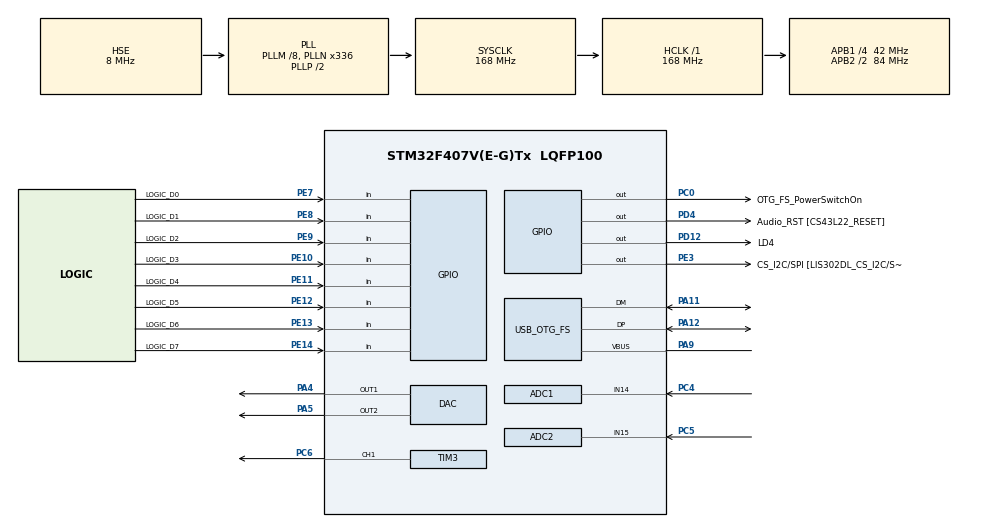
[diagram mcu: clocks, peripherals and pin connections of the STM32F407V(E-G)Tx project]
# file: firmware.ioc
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ADC1.Channel-0\#ChannelRegularConversion=ADC_CHANNEL_14
ADC1.ClockPrescaler=ADC_CLOCK_SYNC_PCLK_DIV4
ADC1.DMAAccessMode=ADC_DMAACCESSMODE_2
ADC1.DMAContinuousRequests=ENABLE
ADC1.ExternalTrigConv=ADC_EXTERNALTRIGCONV_T2_TRGO
ADC1.Mode=ADC_DUALMODE_REGSIMULT
ADC1.NbrOfConversionFlag=1
ADC1.Rank-0\#ChannelRegularConversion=1
ADC1.SamplingTime-0\#ChannelRegularConversion=ADC_SAMPLETIME_3CYCLES
ADC1.master=1
ADC2.Channel-0\#ChannelRegularConversion=ADC_CHANNEL_15
ADC2.ClockPrescaler=ADC_CLOCK_SYNC_PCLK_DIV4
ADC2.DMAAccessMode=ADC_DMAACCESSMODE_2
ADC2.Mode=ADC_DUALMODE_REGSIMULT
ADC2.NbrOfConversionFlag=1
ADC2.Rank-0\#ChannelRegularConversion=1
ADC2.SamplingTime-0\#ChannelRegularConversion=ADC_SAMPLETIME_3CYCLES
DAC.DAC_Trigger=DAC_TRIGGER_T6_TRGO
DAC.DAC_Trigger2=DAC_TRIGGER_T6_TRGO
Dma.ADC1.2.Direction=DMA_PERIPH_TO_MEMORY
Dma.ADC1.2.FIFOMode=DMA_FIFOMODE_DISABLE
Dma.ADC1.2.Instance=DMA2_Stream0
Dma.ADC1.2.MemDataAlignment=DMA_MDATAALIGN_WORD
Dma.ADC1.2.MemInc=DMA_MINC_ENABLE
Dma.ADC1.2.Mode=DMA_NORMAL
Dma.ADC1.2.PeriphDataAlignment=DMA_PDATAALIGN_WORD
Dma.ADC1.2.PeriphInc=DMA_PINC_DISABLE
Dma.ADC1.2.Priority=DMA_PRIORITY_VERY_HIGH
Dma.DAC1.0.Direction=DMA_MEMORY_TO_PERIPH
Dma.DAC1.0.FIFOMode=DMA_FIFOMODE_DISABLE
Dma.DAC1.0.Instance=DMA1_Stream5
Dma.DAC1.0.MemDataAlignment=DMA_MDATAALIGN_HALFWORD
Dma.DAC1.0.MemInc=DMA_MINC_ENABLE
Dma.DAC1.0.Mode=DMA_CIRCULAR
Dma.DAC1.0.PeriphDataAlignment=DMA_PDATAALIGN_HALFWORD
Dma.DAC1.0.PeriphInc=DMA_PINC_DISABLE
Dma.DAC1.0.Priority=DMA_PRIORITY_HIGH
Dma.DAC2.1.Direction=DMA_MEMORY_TO_PERIPH
Dma.DAC2.1.FIFOMode=DMA_FIFOMODE_DISABLE
Dma.DAC2.1.Instance=DMA1_Stream6
Dma.DAC2.1.MemDataAlignment=DMA_MDATAALIGN_HALFWORD
Dma.DAC2.1.MemInc=DMA_MINC_ENABLE
Dma.DAC2.1.Mode=DMA_CIRCULAR
Dma.DAC2.1.PeriphDataAlignment=DMA_PDATAALIGN_HALFWORD
Dma.DAC2.1.PeriphInc=DMA_PINC_DISABLE
Dma.DAC2.1.Priority=DMA_PRIORITY_HIGH
Dma.Request0=DAC1
Dma.Request1=DAC2
Dma.Request2=ADC1
Dma.Request3=TIM1_UP
Dma.TIM1_UP.3.Direction=DMA_PERIPH_TO_MEMORY
Dma.TIM1_UP.3.FIFOMode=DMA_FIFOMODE_ENABLE
Dma.TIM1_UP.3.FIFOThreshold=DMA_FIFO_THRESHOLD_HALFFULL
Dma.TIM1_UP.3.Instance=DMA2_Stream5
Dma.TIM1_UP.3.MemBurst=DMA_MBURST_SINGLE
Dma.TIM1_UP.3.MemDataAlignment=DMA_MDATAALIGN_HALFWORD
Dma.TIM1_UP.3.MemInc=DMA_MINC_ENABLE
Dma.TIM1_UP.3.Mode=DMA_NORMAL
Dma.TIM1_UP.3.PeriphBurst=DMA_PBURST_SINGLE
Dma.TIM1_UP.3.PeriphDataAlignment=DMA_PDATAALIGN_HALFWORD
Dma.TIM1_UP.3.PeriphInc=DMA_PINC_DISABLE
Dma.TIM1_UP.3.Priority=DMA_PRIORITY_VERY_HIGH
Mcu.Family=STM32F4
Mcu.Name=STM32F407V(E-G)Tx
Mcu.Package=LQFP100
NVIC.ADC_IRQn=true\:5\:0\:false\:false\:true\:true\:true\:true
NVIC.DMA1_Stream5_IRQn=true\:5\:0\:false\:false\:true\:false\:true\:true
NVIC.DMA1_Stream6_IRQn=true\:5\:0\:false\:false\:true\:false\:true\:true
NVIC.DMA2_Stream0_IRQn=true\:5\:0\:false\:false\:true\:false\:true\:true
NVIC.DMA2_Stream5_IRQn=true\:5\:0\:false\:false\:true\:false\:true\:true
NVIC.OTG_FS_IRQn=true\:6\:0\:false\:false\:true\:false\:true\:true
NVIC.PriorityGroup=NVIC_PRIORITYGROUP_4
NVIC.TIM6_DAC_IRQn=true\:5\:0\:false\:false\:true\:true\:true\:true
NVIC.TIM7_IRQn=true\:5\:0\:false\:false\:true\:true\:true\:true
NVIC.TimeBase=TIM7_IRQn
NVIC.TimeBaseIP=TIM7
PA11.Mode=Device_Only
PA11.Signal=USB_OTG_FS_DM
PA12.Mode=Device_Only
PA12.Signal=USB_OTG_FS_DP
PA13.GPIO_Label=SWDIO
PA13.Mode=Serial_Wire
PA13.Signal=SYS_JTMS-SWDIO
PA14.GPIO_Label=SWCLK
PA14.Mode=Serial_Wire
PA14.Signal=SYS_JTCK-SWCLK
PA4.Signal=COMP_DAC1_group
PA5.Signal=COMP_DAC2_group
PA9.Mode=Activate_VBUS
PA9.Signal=USB_OTG_FS_VBUS
PC0.GPIO_Label=OTG_FS_PowerSwitchOn
PC0.GPIO_PuPd=GPIO_NOPULL
PC0.GPIO_Speed=GPIO_SPEED_FREQ_LOW
PC0.PinState=GPIO_PIN_SET
PC0.Signal=GPIO_Output
PC4.Signal=ADCx_IN14
PC5.Signal=ADCx_IN15
PC6.Signal=S_TIM3_CH1
PD12.GPIO_Label=LD4
PD12.Signal=GPIO_Output
PD4.GPIO_Label=Audio_RST [CS43L22_RESET]
PD4.GPIO_PuPd=GPIO_NOPULL
PD4.GPIO_Speed=GPIO_SPEED_FREQ_LOW
PD4.Signal=GPIO_Output
PE10.GPIO_Label=LOGIC_D3
PE10.GPIO_PuPd=GPIO_PULLDOWN
PE10.Signal=GPIO_Input
PE11.GPIO_Label=LOGIC_D4
PE11.GPIO_PuPd=GPIO_PULLDOWN
PE11.Signal=GPIO_Input
PE12.GPIO_Label=LOGIC_D5
PE12.GPIO_PuPd=GPIO_PULLDOWN
PE12.Signal=GPIO_Input
PE13.GPIO_Label=LOGIC_D6
PE13.GPIO_PuPd=GPIO_PULLDOWN
PE13.Signal=GPIO_Input
PE14.GPIO_Label=LOGIC_D7
PE14.GPIO_PuPd=GPIO_PULLDOWN
PE14.Signal=GPIO_Input
PE3.GPIO_Label=CS_I2C/SPI [LIS302DL_CS_I2C/SPI]
PE3.GPIO_PuPd=GPIO_NOPULL
PE3.GPIO_Speed=GPIO_SPEED_FREQ_LOW
PE3.PinState=GPIO_PIN_SET
PE3.Signal=GPIO_Output
PE7.GPIO_Label=LOGIC_D0
PE7.GPIO_PuPd=GPIO_PULLDOWN
PE7.Signal=GPIO_Input
PE8.GPIO_Label=LOGIC_D1
PE8.GPIO_PuPd=GPIO_PULLDOWN
PE8.Signal=GPIO_Input
PE9.GPIO_Label=LOGIC_D2
PE9.GPIO_PuPd=GPIO_PULLDOWN
PE9.Signal=GPIO_Input
PH0-OSC_IN.GPIO_Label=PH0-OSC_IN
PH0-OSC_IN.Mode=HSE-External-Oscillator
PH0-OSC_IN.Signal=RCC_OSC_IN
PH1-OSC_OUT.GPIO_Label=PH1-OSC_OUT
PH1-OSC_OUT.Mode=HSE-External-Oscillator
PH1-OSC_OUT.Signal=RCC_OSC_OUT
ProjectManager.HeapSize=0x200
ProjectManager.StackSize=0x400
ProjectManager.TargetToolchain=CMake
RCC.48MHZClocksFreq_Value=48000000
RCC.AHBFreq_Value=168000000
RCC.APB1CLKDivider=RCC_HCLK_DIV4
RCC.APB1Freq_Value=42000000
RCC.APB1TimFreq_Value=84000000
RCC.APB2CLKDivider=RCC_HCLK_DIV2
RCC.APB2Freq_Value=84000000
RCC.APB2TimFreq_Value=168000000
RCC.CortexFreq_Value=168000000
RCC.HCLKFreq_Value=168000000
RCC.HSE_VALUE=8000000
RCC.HSI_VALUE=16000000
RCC.LSE_VALUE=32768
RCC.PLLM=8
RCC.PLLN=336
RCC.PLLQ=7
RCC.SYSCLKFreq_VALUE=168000000
RCC.SYSCLKSource=RCC_SYSCLKSOURCE_PLLCLK
RCC.VCOOutputFreq_Value=336000000
SH.ADCx_IN14.0=ADC1_IN14,IN14
SH.ADCx_IN15.0=ADC2_IN15,IN15
SH.COMP_DAC1_group.0=DAC_OUT1,DAC_OUT1
SH.COMP_DAC2_group.0=DAC_OUT2,DAC_OUT2
SH.S_TIM3_CH1.0=TIM3_CH1,PWM Generation1 CH1
SYS.TimeBase=TIM_TIMEBASE_TIM7
SYS.TimeBaseIP=TIM7
TIM1.Period=167
TIM1.TIM_MasterOutputTrigger=TIM_TRGO_ENABLE
TIM2.Period=839
TIM2.TIM_MasterOutputTrigger=TIM_TRGO_UPDATE
TIM3.Channel-PWM\ Generation1\ CH1=TIM_CHANNEL_1
TIM3.Period=83
TIM3.Prescaler=0
TIM3.Pulse-PWM\ Generation1\ CH1=42
TIM6.AutoReloadPreload=TIM_AUTORELOAD_PRELOAD_ENABLE
TIM6.Period=209
TIM6.TIM_MasterOutputTrigger=TIM_TRGO_UPDATE
USB_DEVICE.APP_RX_DATA_SIZE=64
USB_DEVICE.APP_TX_DATA_SIZE=64
USB_DEVICE.CLASS_NAME_FS=CDC
USB_DEVICE.PRODUCT_STRING_CDC_FS=STM32 Mixed-Signal Instrument
USB_DEVICE.VirtualMode=Cdc
USB_DEVICE.VirtualMode-CDC_FS=Cdc
USB_DEVICE.VirtualModeFS=Cdc_FS
USB_OTG_FS.VirtualMode=Device_Only
USB_OTG_FS.vbus_sensing_enable=ENABLE
VP_SYS_VS_tim7.Mode=TIM7
VP_TIM1_VS_ClockSourceINT.Mode=Internal
VP_TIM2_VS_ClockSourceINT.Mode=Internal
VP_TIM6_VS_ClockSourceINT.Mode=Enable_Timer
VP_USB_DEVICE_VS_USB_DEVICE_CDC_FS.Mode=CDC_FS
board=STM32F407G-DISC1

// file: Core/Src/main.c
/* USER CODE BEGIN Header */
/**
  ******************************************************************************
  * @file           : main.c
  * @brief          : Main program body
  ******************************************************************************
  * @attention
  *
  * Copyright (c) 2026 STMicroelectronics.
  * All rights reserved.
  *
  * This software is licensed under terms that can be found in the LICENSE file
  * in the root directory of this software component.
  * If no LICENSE file comes with this software, it is provided AS-IS.
  *
  ******************************************************************************
  */
/* USER CODE END Header */
#include "main.h"
#include "adc.h"
#include "dac.h"
#include "dma.h"
#include "tim.h"
#include "usb_device.h"
#include "gpio.h"

/* USER CODE BEGIN Includes */
#include "awg.h"
#include "usb_control.h"
#include "scope.h"
#include "logic.h"
#include "probe.h"
#include "cmsis_os2.h"
#include "tasks.h"
/* USER CODE END Includes */

void SystemClock_Config(void);

int main(void)
{

  /* MCU Configuration--------------------------------------------------------*/

  /* Reset of all peripherals, Initializes the Flash interface and the Systick. */
  HAL_Init();

  /* Configure the system clock */
  SystemClock_Config();

  /* Initialize all configured peripherals */
  MX_GPIO_Init();
  MX_DMA_Init();
  MX_DAC_Init();
  MX_TIM2_Init();
  MX_TIM6_Init();
  MX_USB_DEVICE_Init();
  MX_ADC1_Init();
  MX_ADC2_Init();
  MX_TIM1_Init();
  MX_TIM3_Init();
  /* USER CODE BEGIN 2 */
  if (awg_configure(AWG_SINE, 1000U) != AWG_OK || awg_start() != AWG_OK)
  {
    Error_Handler();
  }
  /* The kernel has to start from a region CubeMX actually owns. An invented marker is
     silently dropped the next time the project is regenerated. */
  if (osKernelInitialize() != osOK)
  {
    Error_Handler();
  }
  tasks_create();
  osKernelStart();
  /* osKernelStart only returns if the kernel could not be started. */
  Error_Handler();
  /* USER CODE END 2 */

  /* Infinite loop */
  while (1)
  {

  }
}

void SystemClock_Config(void)
{
  RCC_OscInitTypeDef RCC_OscInitStruct = {0};
  RCC_ClkInitTypeDef RCC_ClkInitStruct = {0};

  /** Configure the main internal regulator output voltage
  */
  __HAL_RCC_PWR_CLK_ENABLE();
  __HAL_PWR_VOLTAGESCALING_CONFIG(PWR_REGULATOR_VOLTAGE_SCALE1);

  /** Initializes the RCC Oscillators according to the specified parameters
  * in the RCC_OscInitTypeDef structure.
  */
  RCC_OscInitStruct.OscillatorType = RCC_OSCILLATORTYPE_HSE;
  RCC_OscInitStruct.HSEState = RCC_HSE_ON;
  RCC_OscInitStruct.PLL.PLLState = RCC_PLL_ON;
  RCC_OscInitStruct.PLL.PLLSource = RCC_PLLSOURCE_HSE;
  RCC_OscInitStruct.PLL.PLLM = 8;
  RCC_OscInitStruct.PLL.PLLN = 336;
  RCC_OscInitStruct.PLL.PLLP = RCC_PLLP_DIV2;
  RCC_OscInitStruct.PLL.PLLQ = 7;
  if (HAL_RCC_OscConfig(&RCC_OscInitStruct) != HAL_OK)
  {
    Error_Handler();
  }

  /** Initializes the CPU, AHB and APB buses clocks
  */
  RCC_ClkInitStruct.ClockType = RCC_CLOCKTYPE_HCLK|RCC_CLOCKTYPE_SYSCLK
                              |RCC_CLOCKTYPE_PCLK1|RCC_CLOCKTYPE_PCLK2;
  RCC_ClkInitStruct.SYSCLKSource = RCC_SYSCLKSOURCE_PLLCLK;
  RCC_ClkInitStruct.AHBCLKDivider = RCC_SYSCLK_DIV1;
  RCC_ClkInitStruct.APB1CLKDivider = RCC_HCLK_DIV4;
  RCC_ClkInitStruct.APB2CLKDivider = RCC_HCLK_DIV2;

  if (HAL_RCC_ClockConfig(&RCC_ClkInitStruct, FLASH_LATENCY_5) != HAL_OK)
  {
    Error_Handler();
  }
}

void HAL_TIM_PeriodElapsedCallback(TIM_HandleTypeDef *htim)
{
  if (htim->Instance == TIM7)
  {
    HAL_IncTick();
  }
}

void Error_Handler(void)
{
  __disable_irq();
  while (1)
  {
  }
}
